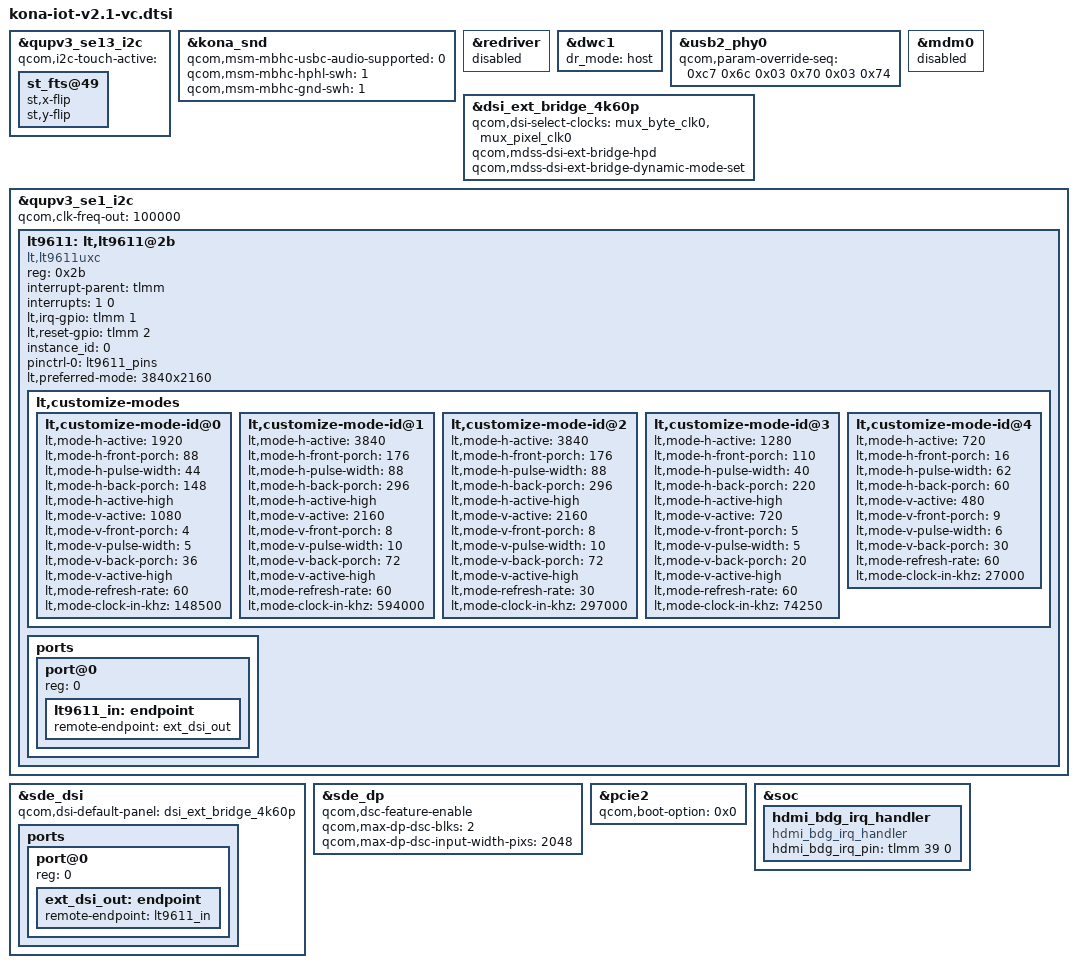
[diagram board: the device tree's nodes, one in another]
#include <dt-bindings/clock/qcom,gcc-kona.h>
#include <dt-bindings/clock/qcom,camcc-kona.h>
#include <dt-bindings/clock/qcom,rpmh.h>
#include <dt-bindings/interrupt-controller/arm-gic.h>

#include "kona-iot-vc.dtsi"

&qupv3_se13_i2c {
	status = "ok";
	qcom,i2c-touch-active = "";

	st_fts@49 {
		st,x-flip;
		st,y-flip;
	};
};

&kona_snd {
	qcom,msm-mbhc-usbc-audio-supported = <0>;
	qcom,msm-mbhc-hphl-swh = <1>;
	qcom,msm-mbhc-gnd-swh = <1>;
};

&redriver {
	status = "disabled";
};

&dwc1 {
	dr_mode = "host";
};

&usb2_phy0 {
	qcom,param-override-seq =
		<0xc7 0x6c
		0x03 0x70
		0x03 0x74>;
};

&mdm0 {
	status = "disabled";
};

&dsi_ext_bridge_4k60p {
	qcom,dsi-select-clocks = "mux_byte_clk0", "mux_pixel_clk0";
	qcom,mdss-dsi-ext-bridge-hpd;
	qcom,mdss-dsi-ext-bridge-dynamic-mode-set;
};

&qupv3_se1_i2c {
	status = "ok";
	qcom,clk-freq-out = <100000>;
	lt9611: lt,lt9611@2b {
		compatible = "lt,lt9611uxc";
		reg = <0x2b>;
		interrupt-parent = <&tlmm>;
		interrupts = <1 0>;
		interrupt-names = "lt_irq";
		lt,irq-gpio = <&tlmm 1 0x0>;
		lt,reset-gpio = <&tlmm 2 0x0>;
		instance_id = <0>;

		pinctrl-names = "default";
		pinctrl-0 = <&lt9611_pins>;

		lt,preferred-mode = "3840x2160";

		lt,customize-modes {
			lt,customize-mode-id@0 {
				lt,mode-h-active = <1920>;
				lt,mode-h-front-porch = <88>;
				lt,mode-h-pulse-width = <44>;
				lt,mode-h-back-porch = <148>;
				lt,mode-h-active-high;
				lt,mode-v-active = <1080>;
				lt,mode-v-front-porch = <4>;
				lt,mode-v-pulse-width = <5>;
				lt,mode-v-back-porch = <36>;
				lt,mode-v-active-high;
				lt,mode-refresh-rate = <60>;
				lt,mode-clock-in-khz = <148500>;
			};
			lt,customize-mode-id@1 {
				lt,mode-h-active = <3840>;
				lt,mode-h-front-porch = <176>;
				lt,mode-h-pulse-width = <88>;
				lt,mode-h-back-porch = <296>;
				lt,mode-h-active-high;
				lt,mode-v-active = <2160>;
				lt,mode-v-front-porch = <8>;
				lt,mode-v-pulse-width = <10>;
				lt,mode-v-back-porch = <72>;
				lt,mode-v-active-high;
				lt,mode-refresh-rate = <60>;
				lt,mode-clock-in-khz = <594000>;
			};
			lt,customize-mode-id@2 {
				lt,mode-h-active = <3840>;
				lt,mode-h-front-porch = <176>;
				lt,mode-h-pulse-width = <88>;
				lt,mode-h-back-porch = <296>;
				lt,mode-h-active-high;
				lt,mode-v-active = <2160>;
				lt,mode-v-front-porch = <8>;
				lt,mode-v-pulse-width = <10>;
				lt,mode-v-back-porch = <72>;
				lt,mode-v-active-high;
				lt,mode-refresh-rate = <30>;
				lt,mode-clock-in-khz = <297000>;
			};


			lt,customize-mode-id@3 {
				lt,mode-h-active = <1280>;
				lt,mode-h-front-porch = <110>;
				lt,mode-h-pulse-width = <40>;
				lt,mode-h-back-porch = <220>;
				lt,mode-h-active-high;
				lt,mode-v-active = <720>;
				lt,mode-v-front-porch = <5>;
				lt,mode-v-pulse-width = <5>;
				lt,mode-v-back-porch = <20>;
				lt,mode-v-active-high;
				lt,mode-refresh-rate = <60>;
				lt,mode-clock-in-khz = <74250>;
			};


			lt,customize-mode-id@4 {
				lt,mode-h-active = <720>;
				lt,mode-h-front-porch = <16>;
				lt,mode-h-pulse-width = <62>;
				lt,mode-h-back-porch = <60>;
				lt,mode-v-active = <480>;
				lt,mode-v-front-porch = <9>;
				lt,mode-v-pulse-width = <6>;
				lt,mode-v-back-porch = <30>;
				lt,mode-refresh-rate = <60>;
				lt,mode-clock-in-khz = <27000>;
			};
		};

		ports {
			#address-cells = <1>;
			#size-cells = <0>;

			port@0 {
				reg = <0>;
				lt9611_in: endpoint {
					remote-endpoint = <&ext_dsi_out>;
				};
			};

		};
	};
};

&sde_dsi {
	qcom,dsi-default-panel = <&dsi_ext_bridge_4k60p>;

	ports {
		#address-cells = <1>;
		#size-cells = <0>;

		port@0 {
			reg = <0>;
			ext_dsi_out: endpoint {
				remote-endpoint = <&lt9611_in>;
			};
		};
	};
};

&sde_dp {
	qcom,dsc-feature-enable;
	qcom,max-dp-dsc-blks = <2>;
	qcom,max-dp-dsc-input-width-pixs = <2048>;
};

&pcie2 {
	qcom,boot-option = <0x0>;
};

&soc {
	hdmi_bdg_irq_handler: hdmi_bdg_irq_handler {
		compatible = "hdmi_bdg_irq_handler";
		hdmi_bdg_irq_pin = <&tlmm 39 0>;
	};
};
